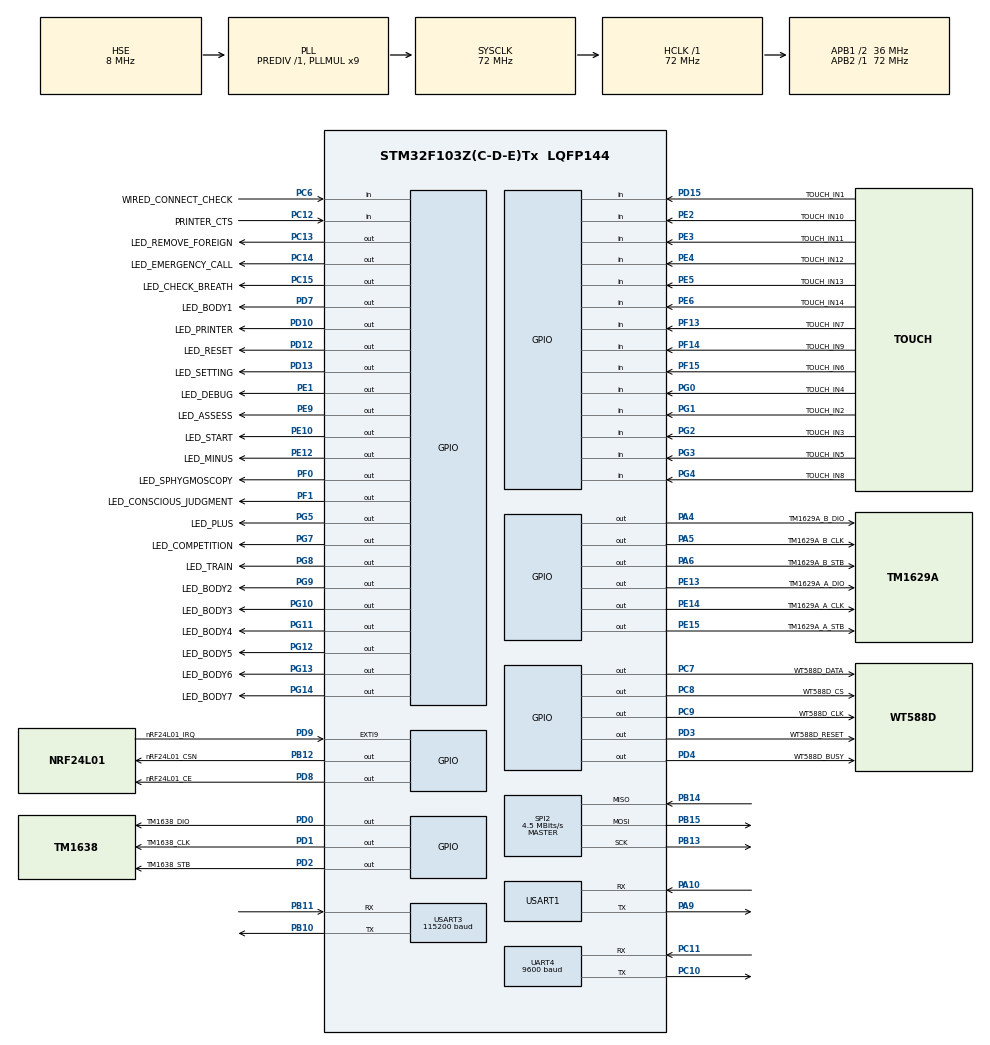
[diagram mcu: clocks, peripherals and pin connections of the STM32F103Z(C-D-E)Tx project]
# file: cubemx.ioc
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Dma.Request0=UART4_RX
Dma.Request1=UART4_TX
Dma.UART4_RX.0.Direction=DMA_PERIPH_TO_MEMORY
Dma.UART4_RX.0.Instance=DMA2_Channel3
Dma.UART4_RX.0.MemDataAlignment=DMA_MDATAALIGN_BYTE
Dma.UART4_RX.0.MemInc=DMA_MINC_ENABLE
Dma.UART4_RX.0.Mode=DMA_NORMAL
Dma.UART4_RX.0.PeriphDataAlignment=DMA_PDATAALIGN_BYTE
Dma.UART4_RX.0.PeriphInc=DMA_PINC_DISABLE
Dma.UART4_RX.0.Priority=DMA_PRIORITY_LOW
Dma.UART4_TX.1.Direction=DMA_MEMORY_TO_PERIPH
Dma.UART4_TX.1.Instance=DMA2_Channel5
Dma.UART4_TX.1.MemDataAlignment=DMA_MDATAALIGN_BYTE
Dma.UART4_TX.1.MemInc=DMA_MINC_ENABLE
Dma.UART4_TX.1.Mode=DMA_NORMAL
Dma.UART4_TX.1.PeriphDataAlignment=DMA_PDATAALIGN_BYTE
Dma.UART4_TX.1.PeriphInc=DMA_PINC_DISABLE
Dma.UART4_TX.1.Priority=DMA_PRIORITY_LOW
Mcu.Family=STM32F1
Mcu.Name=STM32F103Z(C-D-E)Tx
Mcu.Package=LQFP144
NVIC.DMA2_Channel3_IRQn=true\:0\:0\:false\:false\:true\:false\:true\:true
NVIC.DMA2_Channel4_5_IRQn=true\:0\:0\:false\:false\:true\:false\:true\:true
NVIC.PriorityGroup=NVIC_PRIORITYGROUP_4
NVIC.UART4_IRQn=true\:0\:0\:false\:false\:true\:true\:true\:true
OSC_IN.Mode=HSE-External-Oscillator
OSC_IN.Signal=RCC_OSC_IN
OSC_OUT.Mode=HSE-External-Oscillator
OSC_OUT.Signal=RCC_OSC_OUT
PA10.Mode=Asynchronous
PA10.Signal=USART1_RX
PA13.Mode=Serial_Wire
PA13.Signal=SYS_JTMS-SWDIO
PA14.Mode=Serial_Wire
PA14.Signal=SYS_JTCK-SWCLK
PA4.GPIO_Label=TM1629A_B_DIO
PA4.Signal=GPIO_Output
PA5.GPIO_Label=TM1629A_B_CLK
PA5.Signal=GPIO_Output
PA6.GPIO_Label=TM1629A_B_STB
PA6.Signal=GPIO_Output
PA9.Mode=Asynchronous
PA9.Signal=USART1_TX
PB10.Mode=Asynchronous
PB10.Signal=USART3_TX
PB11.Mode=Asynchronous
PB11.Signal=USART3_RX
PB12.GPIO_Label=nRF24L01_CSN
PB12.Signal=GPIO_Output
PB13.Mode=Full_Duplex_Master
PB13.Signal=SPI2_SCK
PB14.Mode=Full_Duplex_Master
PB14.Signal=SPI2_MISO
PB15.Mode=Full_Duplex_Master
PB15.Signal=SPI2_MOSI
PC10.Mode=Asynchronous
PC10.Signal=UART4_TX
PC11.Mode=Asynchronous
PC11.Signal=UART4_RX
PC12.GPIO_Label=PRINTER_CTS
PC12.Signal=GPIO_Input
PC13-TAMPER-RTC.GPIO_Label=LED_REMOVE_FOREIGN
PC13-TAMPER-RTC.Signal=GPIO_Output
PC14-OSC32_IN.GPIO_Label=LED_EMERGENCY_CALL
PC14-OSC32_IN.Signal=GPIO_Output
PC15-OSC32_OUT.GPIO_Label=LED_CHECK_BREATH
PC15-OSC32_OUT.Signal=GPIO_Output
PC6.GPIO_Label=WIRED_CONNECT_CHECK
PC6.Signal=GPIO_Input
PC7.GPIO_Label=WT588D_DATA
PC7.GPIO_PuPd=GPIO_PULLUP
PC7.Signal=GPIO_Output
PC8.GPIO_Label=WT588D_CS
PC8.Signal=GPIO_Output
PC9.GPIO_Label=WT588D_CLK
PC9.Signal=GPIO_Output
PD0.GPIO_Label=TM1638_DIO
PD0.Signal=GPIO_Output
PD1.GPIO_Label=TM1638_CLK
PD1.Signal=GPIO_Output
PD10.GPIO_Label=LED_PRINTER
PD10.Signal=GPIO_Output
PD12.GPIO_Label=LED_RESET
PD12.Signal=GPIO_Output
PD13.GPIO_Label=LED_SETTING
PD13.Signal=GPIO_Output
PD15.GPIO_Label=TOUCH_IN1
PD15.GPIO_PuPd=GPIO_PULLDOWN
PD15.Signal=GPIO_Input
PD2.GPIO_Label=TM1638_STB
PD2.Signal=GPIO_Output
PD3.GPIO_Label=WT588D_RESET
PD3.Signal=GPIO_Output
PD4.GPIO_Label=WT588D_BUSY
PD4.Signal=GPIO_Output
PD7.GPIO_Label=LED_BODY1
PD7.Signal=GPIO_Output
PD8.GPIO_Label=nRF24L01_CE
PD8.Signal=GPIO_Output
PD9.GPIO_Label=nRF24L01_IRQ
PD9.GPIO_ModeDefaultEXTI=GPIO_MODE_IT_FALLING
PD9.GPIO_PuPd=GPIO_PULLUP
PD9.Signal=GPXTI9
PE1.GPIO_Label=LED_DEBUG
PE1.Signal=GPIO_Output
PE10.GPIO_Label=LED_START
PE10.Signal=GPIO_Output
PE12.GPIO_Label=LED_MINUS
PE12.Signal=GPIO_Output
PE13.GPIO_Label=TM1629A_A_DIO
PE13.Signal=GPIO_Output
PE14.GPIO_Label=TM1629A_A_CLK
PE14.Signal=GPIO_Output
PE15.GPIO_Label=TM1629A_A_STB
PE15.Signal=GPIO_Output
PE2.GPIO_Label=TOUCH_IN10
PE2.GPIO_PuPd=GPIO_PULLDOWN
PE2.Signal=GPIO_Input
PE3.GPIO_Label=TOUCH_IN11
PE3.GPIO_PuPd=GPIO_PULLDOWN
PE3.Signal=GPIO_Input
PE4.GPIO_Label=TOUCH_IN12
PE4.GPIO_PuPd=GPIO_PULLDOWN
PE4.Signal=GPIO_Input
PE5.GPIO_Label=TOUCH_IN13
PE5.GPIO_PuPd=GPIO_PULLDOWN
PE5.Signal=GPIO_Input
PE6.GPIO_Label=TOUCH_IN14
PE6.GPIO_PuPd=GPIO_PULLDOWN
PE6.Signal=GPIO_Input
PE9.GPIO_Label=LED_ASSESS
PE9.Signal=GPIO_Output
PF0.GPIO_Label=LED_SPHYGMOSCOPY
PF0.Signal=GPIO_Output
PF1.GPIO_Label=LED_CONSCIOUS_JUDGMENT
PF1.Signal=GPIO_Output
PF13.GPIO_Label=TOUCH_IN7
PF13.GPIO_PuPd=GPIO_PULLDOWN
PF13.Signal=GPIO_Input
PF14.GPIO_Label=TOUCH_IN9
PF14.GPIO_PuPd=GPIO_PULLDOWN
PF14.Signal=GPIO_Input
PF15.GPIO_Label=TOUCH_IN6
PF15.GPIO_PuPd=GPIO_PULLDOWN
PF15.Signal=GPIO_Input
PG0.GPIO_Label=TOUCH_IN4
PG0.GPIO_PuPd=GPIO_PULLDOWN
PG0.Signal=GPIO_Input
PG1.GPIO_Label=TOUCH_IN2
PG1.GPIO_PuPd=GPIO_PULLDOWN
PG1.Signal=GPIO_Input
PG10.GPIO_Label=LED_BODY3
PG10.Signal=GPIO_Output
PG11.GPIO_Label=LED_BODY4
PG11.Signal=GPIO_Output
PG12.GPIO_Label=LED_BODY5
PG12.Signal=GPIO_Output
PG13.GPIO_Label=LED_BODY6
PG13.Signal=GPIO_Output
PG14.GPIO_Label=LED_BODY7
PG14.Signal=GPIO_Output
PG2.GPIO_Label=TOUCH_IN3
PG2.GPIO_PuPd=GPIO_PULLDOWN
PG2.Signal=GPIO_Input
PG3.GPIO_Label=TOUCH_IN5
PG3.GPIO_PuPd=GPIO_PULLDOWN
PG3.Signal=GPIO_Input
PG4.GPIO_Label=TOUCH_IN8
PG4.GPIO_PuPd=GPIO_PULLDOWN
PG4.Signal=GPIO_Input
PG5.GPIO_Label=LED_PLUS
PG5.Signal=GPIO_Output
PG7.GPIO_Label=LED_COMPETITION
PG7.Signal=GPIO_Output
PG8.GPIO_Label=LED_TRAIN
PG8.Signal=GPIO_Output
PG9.GPIO_Label=LED_BODY2
PG9.Signal=GPIO_Output
ProjectManager.HeapSize=0x200
ProjectManager.StackSize=0x400
ProjectManager.TargetToolchain=MDK-ARM V5.32
RCC.AHBFreq_Value=72000000
RCC.APB1CLKDivider=RCC_HCLK_DIV2
RCC.APB1Freq_Value=36000000
RCC.APB1TimFreq_Value=72000000
RCC.APB2Freq_Value=72000000
RCC.APB2TimFreq_Value=72000000
RCC.HCLKFreq_Value=72000000
RCC.PLLMUL=RCC_PLL_MUL9
RCC.PLLSourceVirtual=RCC_PLLSOURCE_HSE
RCC.SYSCLKFreq_VALUE=72000000
RCC.SYSCLKSource=RCC_SYSCLKSOURCE_PLLCLK
RCC.USBFreq_Value=72000000
SPI2.BaudRatePrescaler=SPI_BAUDRATEPRESCALER_8
SPI2.CalculateBaudRate=4.5 MBits/s
SPI2.Direction=SPI_DIRECTION_2LINES
SPI2.Mode=SPI_MODE_MASTER
SPI2.VirtualType=VM_MASTER
UART4.BaudRate=9600
UART4.VirtualMode=Asynchronous
USART1.VirtualMode=VM_ASYNC
USART3.BaudRate=115200
USART3.Parity=PARITY_NONE
USART3.VirtualMode=VM_ASYNC
board=custom

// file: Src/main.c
/* USER CODE BEGIN Header */
/**
  ******************************************************************************
  * @file           : main.c
  * @brief          : Main program body
  ******************************************************************************
  * @attention
  *
  * Copyright (c) 2025 STMicroelectronics.
  * All rights reserved.
  *
  * This software is licensed under terms that can be found in the LICENSE file
  * in the root directory of this software component.
  * If no LICENSE file comes with this software, it is provided AS-IS.
  *
  ******************************************************************************
  */
/* USER CODE END Header */
#include "main.h"

/* USER CODE BEGIN Includes */
#include "bsp_sys.h"
/* USER CODE END Includes */

SPI_HandleTypeDef hspi2;

UART_HandleTypeDef huart4;
UART_HandleTypeDef huart1;
UART_HandleTypeDef huart3;
DMA_HandleTypeDef hdma_uart4_rx;
DMA_HandleTypeDef hdma_uart4_tx;
DMA_HandleTypeDef hdma_usart3_rx;
DMA_HandleTypeDef hdma_usart3_tx;

__WEAK int main(void)
{

  /* MCU Configuration--------------------------------------------------------*/

  /* Reset of all peripherals, Initializes the Flash interface and the Systick. */
  HAL_Init();

  /* Configure the system clock */
  SystemClock_Config();

  /* Initialize all configured peripherals */
  MX_GPIO_Init();
  MX_DMA_Init();
  MX_USART1_UART_Init();
  MX_UART4_Init();
  MX_USART3_UART_Init();
  MX_SPI2_Init();

  /* Infinite loop */
  while (1)
  {

  }
}

void SystemClock_Config(void)
{
  RCC_OscInitTypeDef RCC_OscInitStruct = {0};
  RCC_ClkInitTypeDef RCC_ClkInitStruct = {0};

  /** Initializes the RCC Oscillators according to the specified parameters
  * in the RCC_OscInitTypeDef structure.
  */
  RCC_OscInitStruct.OscillatorType = RCC_OSCILLATORTYPE_HSE;
  RCC_OscInitStruct.HSEState = RCC_HSE_ON;
  RCC_OscInitStruct.HSEPredivValue = RCC_HSE_PREDIV_DIV1;
  RCC_OscInitStruct.HSIState = RCC_HSI_ON;
  RCC_OscInitStruct.PLL.PLLState = RCC_PLL_ON;
  RCC_OscInitStruct.PLL.PLLSource = RCC_PLLSOURCE_HSE;
  RCC_OscInitStruct.PLL.PLLMUL = RCC_PLL_MUL9;
  if (HAL_RCC_OscConfig(&RCC_OscInitStruct) != HAL_OK)
  {
    Error_Handler();
  }

  /** Initializes the CPU, AHB and APB buses clocks
  */
  RCC_ClkInitStruct.ClockType = RCC_CLOCKTYPE_HCLK|RCC_CLOCKTYPE_SYSCLK
                              |RCC_CLOCKTYPE_PCLK1|RCC_CLOCKTYPE_PCLK2;
  RCC_ClkInitStruct.SYSCLKSource = RCC_SYSCLKSOURCE_PLLCLK;
  RCC_ClkInitStruct.AHBCLKDivider = RCC_SYSCLK_DIV1;
  RCC_ClkInitStruct.APB1CLKDivider = RCC_HCLK_DIV2;
  RCC_ClkInitStruct.APB2CLKDivider = RCC_HCLK_DIV1;

  if (HAL_RCC_ClockConfig(&RCC_ClkInitStruct, FLASH_LATENCY_2) != HAL_OK)
  {
    Error_Handler();
  }
}

void MX_SPI2_Init(void)
{

  /* SPI2 parameter configuration*/
  hspi2.Instance = SPI2;
  hspi2.Init.Mode = SPI_MODE_MASTER;
  hspi2.Init.Direction = SPI_DIRECTION_2LINES;
  hspi2.Init.DataSize = SPI_DATASIZE_8BIT;
  hspi2.Init.CLKPolarity = SPI_POLARITY_LOW;
  hspi2.Init.CLKPhase = SPI_PHASE_1EDGE;
  hspi2.Init.NSS = SPI_NSS_SOFT;
  hspi2.Init.BaudRatePrescaler = SPI_BAUDRATEPRESCALER_8;
  hspi2.Init.FirstBit = SPI_FIRSTBIT_MSB;
  hspi2.Init.TIMode = SPI_TIMODE_DISABLE;
  hspi2.Init.CRCCalculation = SPI_CRCCALCULATION_DISABLE;
  hspi2.Init.CRCPolynomial = 10;
  if (HAL_SPI_Init(&hspi2) != HAL_OK)
  {
    Error_Handler();
  }

}

void MX_UART4_Init(void)
{

  huart4.Instance = UART4;
  huart4.Init.BaudRate = 9600;
  huart4.Init.WordLength = UART_WORDLENGTH_8B;
  huart4.Init.StopBits = UART_STOPBITS_1;
  huart4.Init.Parity = UART_PARITY_NONE;
  huart4.Init.Mode = UART_MODE_TX_RX;
  huart4.Init.HwFlowCtl = UART_HWCONTROL_NONE;
  huart4.Init.OverSampling = UART_OVERSAMPLING_16;
  if (HAL_UART_Init(&huart4) != HAL_OK)
  {
    Error_Handler();
  }

}

void MX_USART1_UART_Init(void)
{

  huart1.Instance = USART1;
  huart1.Init.BaudRate = 115200;
  huart1.Init.WordLength = UART_WORDLENGTH_8B;
  huart1.Init.StopBits = UART_STOPBITS_1;
  huart1.Init.Parity = UART_PARITY_NONE;
  huart1.Init.Mode = UART_MODE_TX_RX;
  huart1.Init.HwFlowCtl = UART_HWCONTROL_NONE;
  huart1.Init.OverSampling = UART_OVERSAMPLING_16;
  if (HAL_UART_Init(&huart1) != HAL_OK)
  {
    Error_Handler();
  }

}

void MX_USART3_UART_Init(void)
{

  huart3.Instance = USART3;
  huart3.Init.BaudRate = 115200;
  huart3.Init.WordLength = UART_WORDLENGTH_8B;
  huart3.Init.StopBits = UART_STOPBITS_1;
  huart3.Init.Parity = UART_PARITY_NONE;
  huart3.Init.Mode = UART_MODE_TX_RX;
  huart3.Init.HwFlowCtl = UART_HWCONTROL_NONE;
  huart3.Init.OverSampling = UART_OVERSAMPLING_16;
  if (HAL_UART_Init(&huart3) != HAL_OK)
  {
    Error_Handler();
  }

}

void MX_DMA_Init(void)
{

  /* DMA controller clock enable */
  __HAL_RCC_DMA1_CLK_ENABLE();
  __HAL_RCC_DMA2_CLK_ENABLE();

  /* DMA interrupt init */
  /* DMA1_Channel2_IRQn interrupt configuration */
  HAL_NVIC_SetPriority(DMA1_Channel2_IRQn, 0, 0);
  HAL_NVIC_EnableIRQ(DMA1_Channel2_IRQn);
  /* DMA1_Channel3_IRQn interrupt configuration */
  HAL_NVIC_SetPriority(DMA1_Channel3_IRQn, 0, 0);
  HAL_NVIC_EnableIRQ(DMA1_Channel3_IRQn);
  /* DMA2_Channel3_IRQn interrupt configuration */
  HAL_NVIC_SetPriority(DMA2_Channel3_IRQn, 0, 0);
  HAL_NVIC_EnableIRQ(DMA2_Channel3_IRQn);
  /* DMA2_Channel4_5_IRQn interrupt configuration */
  HAL_NVIC_SetPriority(DMA2_Channel4_5_IRQn, 0, 0);
  HAL_NVIC_EnableIRQ(DMA2_Channel4_5_IRQn);

}

void MX_GPIO_Init(void)
{
  GPIO_InitTypeDef GPIO_InitStruct = {0};

  /* GPIO Ports Clock Enable */
  __HAL_RCC_GPIOE_CLK_ENABLE();
  __HAL_RCC_GPIOC_CLK_ENABLE();
  __HAL_RCC_GPIOF_CLK_ENABLE();
  __HAL_RCC_GPIOA_CLK_ENABLE();
  __HAL_RCC_GPIOG_CLK_ENABLE();
  __HAL_RCC_GPIOB_CLK_ENABLE();
  __HAL_RCC_GPIOD_CLK_ENABLE();

  /*Configure GPIO pin Output Level */
  HAL_GPIO_WritePin(GPIOC, LED_REMOVE_FOREIGN_Pin|LED_EMERGENCY_CALL_Pin|LED_CHECK_BREATH_Pin|WT588D_DATA_Pin
                          |WT588D_CS_Pin|WT588D_CLK_Pin, GPIO_PIN_RESET);

  /*Configure GPIO pin Output Level */
  HAL_GPIO_WritePin(GPIOF, LED_SPHYGMOSCOPY_Pin|LED_CONSCIOUS_JUDGMENT_Pin, GPIO_PIN_RESET);

  /*Configure GPIO pin Output Level */
  HAL_GPIO_WritePin(GPIOA, TM1629A_B_DIO_Pin|TM1629A_B_CLK_Pin|TM1629A_B_STB_Pin, GPIO_PIN_RESET);

  /*Configure GPIO pin Output Level */
  HAL_GPIO_WritePin(GPIOE, LED_ASSESS_Pin|LED_START_Pin|LED_MINUS_Pin|TM1629A_A_DIO_Pin
                          |TM1629A_A_CLK_Pin|TM1629A_A_STB_Pin|LED_DEBUG_Pin, GPIO_PIN_RESET);

  /*Configure GPIO pin Output Level */
  HAL_GPIO_WritePin(nRF24L01_CSN_GPIO_Port, nRF24L01_CSN_Pin, GPIO_PIN_RESET);

  /*Configure GPIO pin Output Level */
  HAL_GPIO_WritePin(GPIOD, nRF24L01_CE_Pin|LED_PRINTER_Pin|LED_RESET_Pin|LED_SETTING_Pin
                          |TM1638_DIO_Pin|TM1638_CLK_Pin|TM1638_STB_Pin|WT588D_RESET_Pin
                          |WT588D_BUSY_Pin|LED_BODY1_Pin, GPIO_PIN_RESET);

  /*Configure GPIO pin Output Level */
  HAL_GPIO_WritePin(GPIOG, LED_PLUS_Pin|LED_COMPETITION_Pin|LED_TRAIN_Pin|LED_BODY2_Pin
                          |LED_BODY3_Pin|LED_BODY4_Pin|LED_BODY5_Pin|LED_BODY6_Pin
                          |LED_BODY7_Pin, GPIO_PIN_RESET);

  /*Configure GPIO pins : TOUCH_IN10_Pin TOUCH_IN11_Pin TOUCH_IN12_Pin TOUCH_IN13_Pin
                           TOUCH_IN14_Pin */
  GPIO_InitStruct.Pin = TOUCH_IN10_Pin|TOUCH_IN11_Pin|TOUCH_IN12_Pin|TOUCH_IN13_Pin
                          |TOUCH_IN14_Pin;
  GPIO_InitStruct.Mode = GPIO_MODE_INPUT;
  GPIO_InitStruct.Pull = GPIO_PULLDOWN;
  HAL_GPIO_Init(GPIOE, &GPIO_InitStruct);

  /*Configure GPIO pins : LED_REMOVE_FOREIGN_Pin LED_EMERGENCY_CALL_Pin LED_CHECK_BREATH_Pin WT588D_CS_Pin
                           WT588D_CLK_Pin */
  GPIO_InitStruct.Pin = LED_REMOVE_FOREIGN_Pin|LED_EMERGENCY_CALL_Pin|LED_CHECK_BREATH_Pin|WT588D_CS_Pin
                          |WT588D_CLK_Pin;
  GPIO_InitStruct.Mode = GPIO_MODE_OUTPUT_PP;
  GPIO_InitStruct.Pull = GPIO_NOPULL;
  GPIO_InitStruct.Speed = GPIO_SPEED_FREQ_LOW;
  HAL_GPIO_Init(GPIOC, &GPIO_InitStruct);

  /*Configure GPIO pins : LED_SPHYGMOSCOPY_Pin LED_CONSCIOUS_JUDGMENT_Pin */
  GPIO_InitStruct.Pin = LED_SPHYGMOSCOPY_Pin|LED_CONSCIOUS_JUDGMENT_Pin;
  GPIO_InitStruct.Mode = GPIO_MODE_OUTPUT_PP;
  GPIO_InitStruct.Pull = GPIO_NOPULL;
  GPIO_InitStruct.Speed = GPIO_SPEED_FREQ_LOW;
  HAL_GPIO_Init(GPIOF, &GPIO_InitStruct);

  /*Configure GPIO pins : TM1629A_B_DIO_Pin TM1629A_B_CLK_Pin TM1629A_B_STB_Pin */
  GPIO_InitStruct.Pin = TM1629A_B_DIO_Pin|TM1629A_B_CLK_Pin|TM1629A_B_STB_Pin;
  GPIO_InitStruct.Mode = GPIO_MODE_OUTPUT_PP;
  GPIO_InitStruct.Pull = GPIO_NOPULL;
  GPIO_InitStruct.Speed = GPIO_SPEED_FREQ_LOW;
  HAL_GPIO_Init(GPIOA, &GPIO_InitStruct);

  /*Configure GPIO pins : TOUCH_IN7_Pin TOUCH_IN9_Pin TOUCH_IN6_Pin */
  GPIO_InitStruct.Pin = TOUCH_IN7_Pin|TOUCH_IN9_Pin|TOUCH_IN6_Pin;
  GPIO_InitStruct.Mode = GPIO_MODE_INPUT;
  GPIO_InitStruct.Pull = GPIO_PULLDOWN;
  HAL_GPIO_Init(GPIOF, &GPIO_InitStruct);

  /*Configure GPIO pins : TOUCH_IN4_Pin TOUCH_IN2_Pin TOUCH_IN3_Pin TOUCH_IN5_Pin
                           TOUCH_IN8_Pin */
  GPIO_InitStruct.Pin = TOUCH_IN4_Pin|TOUCH_IN2_Pin|TOUCH_IN3_Pin|TOUCH_IN5_Pin
                          |TOUCH_IN8_Pin;
  GPIO_InitStruct.Mode = GPIO_MODE_INPUT;
  GPIO_InitStruct.Pull = GPIO_PULLDOWN;
  HAL_GPIO_Init(GPIOG, &GPIO_InitStruct);

  /*Configure GPIO pins : LED_ASSESS_Pin LED_START_Pin LED_MINUS_Pin TM1629A_A_DIO_Pin
                           TM1629A_A_CLK_Pin TM1629A_A_STB_Pin LED_DEBUG_Pin */
  GPIO_InitStruct.Pin = LED_ASSESS_Pin|LED_START_Pin|LED_MINUS_Pin|TM1629A_A_DIO_Pin
                          |TM1629A_A_CLK_Pin|TM1629A_A_STB_Pin|LED_DEBUG_Pin;
  GPIO_InitStruct.Mode = GPIO_MODE_OUTPUT_PP;
  GPIO_InitStruct.Pull = GPIO_NOPULL;
  GPIO_InitStruct.Speed = GPIO_SPEED_FREQ_LOW;
  HAL_GPIO_Init(GPIOE, &GPIO_InitStruct);

  /*Configure GPIO pin : nRF24L01_CSN_Pin */
  GPIO_InitStruct.Pin = nRF24L01_CSN_Pin;
  GPIO_InitStruct.Mode = GPIO_MODE_OUTPUT_PP;
  GPIO_InitStruct.Pull = GPIO_NOPULL;
  GPIO_InitStruct.Speed = GPIO_SPEED_FREQ_LOW;
  HAL_GPIO_Init(nRF24L01_CSN_GPIO_Port, &GPIO_InitStruct);

  /*Configure GPIO pins : nRF24L01_CE_Pin LED_PRINTER_Pin LED_RESET_Pin LED_SETTING_Pin
                           TM1638_DIO_Pin TM1638_CLK_Pin TM1638_STB_Pin WT588D_RESET_Pin
                           WT588D_BUSY_Pin LED_BODY1_Pin */
  GPIO_InitStruct.Pin = nRF24L01_CE_Pin|LED_PRINTER_Pin|LED_RESET_Pin|LED_SETTING_Pin
                          |TM1638_DIO_Pin|TM1638_CLK_Pin|TM1638_STB_Pin|WT588D_RESET_Pin
                          |WT588D_BUSY_Pin|LED_BODY1_Pin;
  GPIO_InitStruct.Mode = GPIO_MODE_OUTPUT_PP;
  GPIO_InitStruct.Pull = GPIO_NOPULL;
  GPIO_InitStruct.Speed = GPIO_SPEED_FREQ_LOW;
  HAL_GPIO_Init(GPIOD, &GPIO_InitStruct);

  /*Configure GPIO pin : nRF24L01_IRQ_Pin */
  GPIO_InitStruct.Pin = nRF24L01_IRQ_Pin;
  GPIO_InitStruct.Mode = GPIO_MODE_IT_FALLING;
  GPIO_InitStruct.Pull = GPIO_PULLUP;
  HAL_GPIO_Init(nRF24L01_IRQ_GPIO_Port, &GPIO_InitStruct);

  /*Configure GPIO pin : TOUCH_IN1_Pin */
  GPIO_InitStruct.Pin = TOUCH_IN1_Pin;
  GPIO_InitStruct.Mode = GPIO_MODE_INPUT;
  GPIO_InitStruct.Pull = GPIO_PULLDOWN;
  HAL_GPIO_Init(TOUCH_IN1_GPIO_Port, &GPIO_InitStruct);

  /*Configure GPIO pins : LED_PLUS_Pin LED_COMPETITION_Pin LED_TRAIN_Pin LED_BODY2_Pin
                           LED_BODY3_Pin LED_BODY4_Pin LED_BODY5_Pin LED_BODY6_Pin
                           LED_BODY7_Pin */
  GPIO_InitStruct.Pin = LED_PLUS_Pin|LED_COMPETITION_Pin|LED_TRAIN_Pin|LED_BODY2_Pin
                          |LED_BODY3_Pin|LED_BODY4_Pin|LED_BODY5_Pin|LED_BODY6_Pin
                          |LED_BODY7_Pin;
  GPIO_InitStruct.Mode = GPIO_MODE_OUTPUT_PP;
  GPIO_InitStruct.Pull = GPIO_NOPULL;
  GPIO_InitStruct.Speed = GPIO_SPEED_FREQ_LOW;
  HAL_GPIO_Init(GPIOG, &GPIO_InitStruct);

  /*Configure GPIO pins : WIRED_CONNECT_CHECK_Pin PRINTER_CTS_Pin */
  GPIO_InitStruct.Pin = WIRED_CONNECT_CHECK_Pin|PRINTER_CTS_Pin;
  GPIO_InitStruct.Mode = GPIO_MODE_INPUT;
  GPIO_InitStruct.Pull = GPIO_NOPULL;
  HAL_GPIO_Init(GPIOC, &GPIO_InitStruct);

  /*Configure GPIO pin : WT588D_DATA_Pin */
  GPIO_InitStruct.Pin = WT588D_DATA_Pin;
  GPIO_InitStruct.Mode = GPIO_MODE_OUTPUT_PP;
  GPIO_InitStruct.Pull = GPIO_PULLUP;
  GPIO_InitStruct.Speed = GPIO_SPEED_FREQ_LOW;
  HAL_GPIO_Init(WT588D_DATA_GPIO_Port, &GPIO_InitStruct);

}
